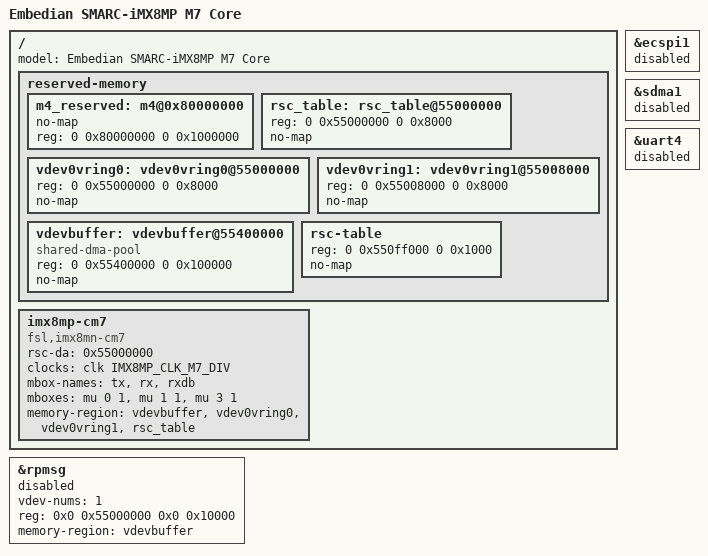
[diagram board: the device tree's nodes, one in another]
// SPDX-License-Identifier: (GPL-2.0 OR MIT)
/*
 * Copyright 2020 NXP
 * Copyright 2021-2022 Embedian, Inc.
 */

/dts-v1/;

#include "imx8mp-smarc.dts"

/ {
	model = "Embedian SMARC-iMX8MP M7 Core";
	reserved-memory {
		#address-cells = <2>;
		#size-cells = <2>;
		ranges;

		m4_reserved: m4@0x80000000 {
			no-map;
			reg = <0 0x80000000 0 0x1000000>;
		};

		rsc_table: rsc_table@55000000 {
			reg = <0 0x55000000 0 0x8000>;
			no-map;
		};

		vdev0vring0: vdev0vring0@55000000 {
			reg = <0 0x55000000 0 0x8000>;
			no-map;
		};

		vdev0vring1: vdev0vring1@55008000 {
			reg = <0 0x55008000 0 0x8000>;
			no-map;
		};

		vdevbuffer: vdevbuffer@55400000 {
			compatible = "shared-dma-pool";
			reg = <0 0x55400000 0 0x100000>;
			no-map;
		};

		rsc-table {
			reg = <0 0x550ff000 0 0x1000>;
			no-map;
		};
	};

	imx8mp-cm7 {
		compatible = "fsl,imx8mn-cm7";
		rsc-da = <0x55000000>;
		clocks = <&clk IMX8MP_CLK_M7_DIV>;
		mbox-names = "tx", "rx", "rxdb";
		mboxes = <&mu 0 1
			  &mu 1 1
			  &mu 3 1>;
		memory-region = <&vdevbuffer>, <&vdev0vring0>, <&vdev0vring1>, <&rsc_table>;
		status = "okay";
	};
};

/*
 * ATTENTION: M7 may use IPs like below
 * ECSPI1, GPT1, I2C3, UART4, PWM1, SDMA1
 */
&ecspi1 {
	status = "disabled";
};

&rpmsg{
	/*
	 * 64K for one rpmsg instance:
	 * --0x55000000~0x5500ffff: pingpong
	 */
	vdev-nums = <1>;
	reg = <0x0 0x55000000 0x0 0x10000>;
	memory-region = <&vdevbuffer>;
	status = "disabled";
};

&sdma1{
	status = "disabled";
};

&uart4 {
	/* SER1 */
	status = "disabled";
};
